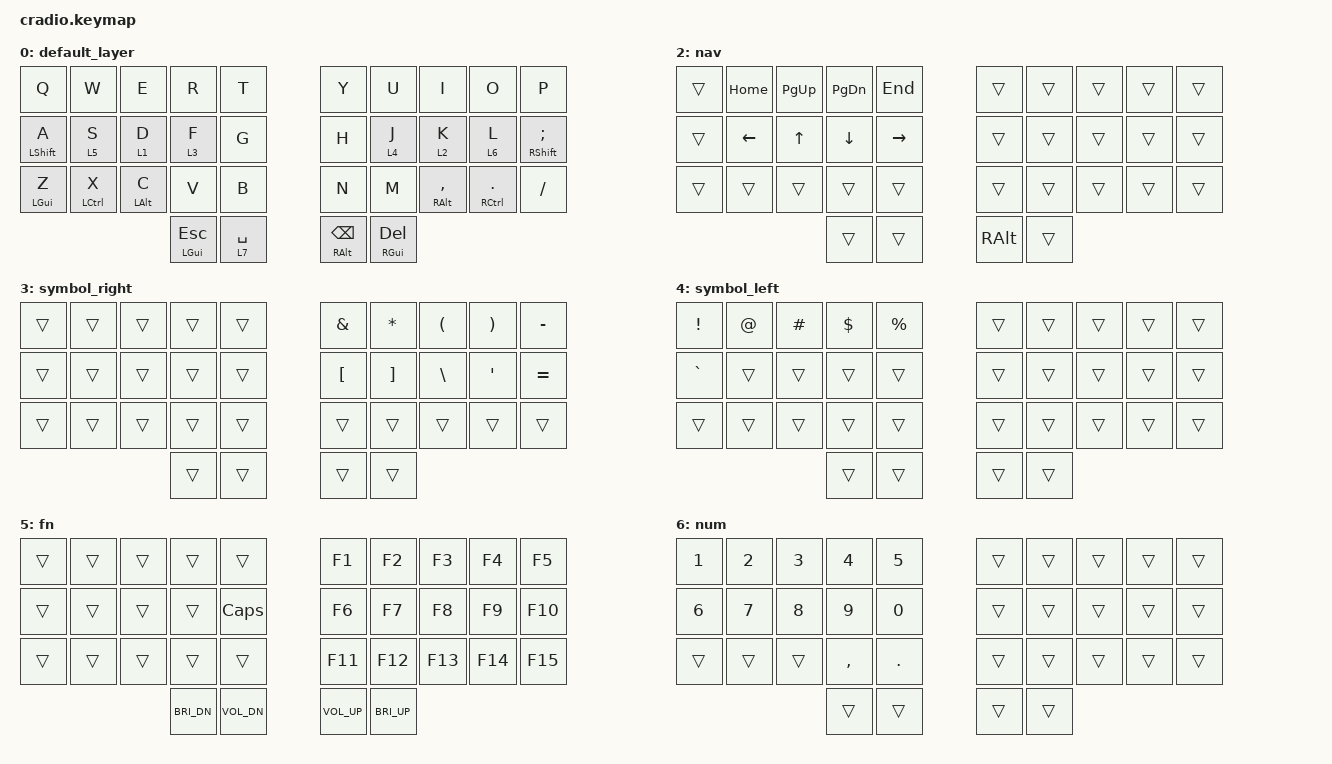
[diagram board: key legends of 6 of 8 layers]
// Copyright (c) 2022 The ZMK Contributors
// SPDX-License-Identifier: MIT

#include <behaviors.dtsi>
#include <dt-bindings/zmk/keys.h>
#include <dt-bindings/zmk/bt.h>
#include <dt-bindings/zmk/mouse.h>
#include <behaviors/mouse_keys.dtsi>


// Home row mods macro
#define HRML(k1,k2,k3,k4) &ht LSHFT k1  &ht LCTRL k2  &ht LALT k3  &ht LGUI k4
#define HRMR(k1,k2,k3,k4) &ht RGUI k1   &ht RALT k2   &ht RCTRL k3 &ht RSHFT k4
#define BTCN(s1,s2,s3,s4,s5) &bt BT_SEL s1 &bt BT_SEL s2 &bt BT_SEL s3 &bt BT_SEL s4 &bt BT_SEL s5
#define BTDN(s1,s2,s3,s4,s5) &bt BT_DISC s1 &bt BT_DISC s2 &bt BT_DISC s3 &bt BT_DISC s4 &bt BT_DISC s5

#define ZMK_MOUSE_DEFAULT_MOVE_VAL 1500  // 600
#define ZMK_MOUSE_DEFAULT_SCRL_VAL 20    // 10

&mmv {
  acceleration-exponent = <1>;      // 1
  time-to-max-speed-ms = <500>;    // 40
  delay-ms = <0>;                   // 0
};

&msc {
  acceleration-exponent = <1>;      // 0
  time-to-max-speed-ms = <500>;      // 500
  delay-ms = <0>;                   // 10
};

#define U_MS_U &mmv MOVE_UP
#define U_MS_D &mmv MOVE_DOWN
#define U_MS_L &mmv MOVE_LEFT
#define U_MS_R &mmv MOVE_RIGHT
#define U_WH_U &msc SCRL_UP
#define U_WH_D &msc SCRL_DOWN
#define U_WH_L &msc SCRL_LEFT
#define U_WH_R &msc SCRL_RIGHT

#define MOUSE() &mkp LCLK &mkp RCLK &mkp MCLK
#define MMV() U_MS_L U_MS_D U_MS_U U_MS_R
#define MSC() U_WH_L U_WH_D U_WH_U U_WH_R


// num, nav, fn, mouse
#define THUMB() &mo 1 &lt 2 SPACE &lt 3 ENTER &lt 4 BSPC

/ {
    behaviors {
        ht: hold_tap {
            label = "hold_tap";
            compatible = "zmk,behavior-hold-tap";
            #binding-cells = <2>;
            flavor = "tap-preferred";
            tapping-term-ms = <200>;
            quick-tap-ms = <150>;
            require-prior-idle-ms = <100>;
            bindings = <&kp>, <&kp>;
        };
    };

    keymap {
        compatible = "zmk,keymap";
        default_layer {
            bindings = <
        //╭──────────┬──────────┬──────────┬──────────┬──────────╮   ╭──────────┬──────────┬──────────┬──────────┬──────────╮
        //│  Q       │  W       │  E       │  R       │  T       │   │  Y       │  U       │  I       │  O       │  P       │
            &kp Q      &kp W      &kp E      &kp R      &kp T          &kp Y      &kp U      &kp I      &kp O      &kp P
        //├──────────┼──────────┼──────────┼──────────┼──────────┤   ├──────────┼──────────┼──────────┼──────────┼──────────┤
        //│  A       │  S       │  D       │  F       │  G       │   │  H       │  J       │  K       │  L       │ ; :      │
           &ht LSHFT A  &lt 5 S   &lt 1 D    &lt 3 F    &kp G          &kp H      &lt 4 J    &lt 2 K    &lt 6 L    &ht RSHFT SEMI
        //├──────────┼──────────┼──────────┼──────────┼──────────┤   ├──────────┼──────────┼──────────┼──────────┼──────────┤
        //│  Z       │  X       │  C       │  V       │  B       │   │  N       │  M       │ , <      │ . >      │ / ?      │
            &ht LGUI Z &ht LCTRL X &ht LALT C &kp V      &kp B         &kp N     &kp M       &ht RALT COMMA  &ht RCTRL DOT &kp FSLH
        //╰──────────┴──────────┴──────────┼──────────┼──────────┤   ├──────────┼──────────┼──────────┴──────────┴──────────╯
                                             &ht LGUI ESC &lt 7 SPACE &ht RALT BSPC &ht RGUI DEL
        //                                 ╰──────────┴──────────╯   ╰──────────┴──────────╯
            >;
        };

        mouse {
            bindings = <
        //╭──────────┬──────────┬──────────┬──────────┬──────────╮   ╭──────────┬──────────┬──────────┬──────────┬──────────╮
        //│          │          │          │          │          │   │          │          │          │          │          │
            &trans     &trans     &trans     &trans     &trans         MSC()                                       &trans
        //├──────────┼──────────┼──────────┼──────────┼──────────┤   ├──────────┼──────────┼──────────┼──────────┼──────────┤
        //│          │          │          │          │          │   │          │          │          │          │          │
            &trans     &trans     &trans     &trans     &trans         MMV()                                       &trans
        //├──────────┼──────────┼──────────┼──────────┼──────────┤   ├──────────┼──────────┼──────────┼──────────┼──────────┤
        //│          │          │          │          │          │   │          │          │          │          │          │
            &trans     &trans     &trans     &trans     &trans         &trans     MOUSE()                          &trans
        //╰──────────┴──────────┴──────────┼──────────┼──────────┤   ├──────────┼──────────┼──────────┴──────────┴──────────╯
                                             &trans     &trans         &trans     &trans
        //                                 ╰──────────┴──────────╯   ╰──────────┴──────────╯
            >;
        };

        nav {
            bindings = <
        //╭──────────┬──────────┬──────────┬──────────┬──────────╮   ╭──────────┬──────────┬──────────┬──────────┬──────────╮
        //│          │          │          │          │          │   │          │          │          │          │          │
            &trans     &kp HOME   &kp PG_UP  &kp PG_DN  &kp END        &trans     &trans     &trans     &trans     &trans
        //├──────────┼──────────┼──────────┼──────────┼──────────┤   ├──────────┼──────────┼──────────┼──────────┼──────────┤
        //│          │          │          │          │          │   │          │          │          │          │          │
            &trans     &kp LEFT   &kp UP     &kp DOWN   &kp RIGHT      &trans     &trans     &trans     &trans     &trans
        //├──────────┼──────────┼──────────┼──────────┼──────────┤   ├──────────┼──────────┼──────────┼──────────┼──────────┤
        //│          │          │          │          │          │   │          │          │          │          │          │
            &trans     &trans     &trans     &trans     &trans         &trans     &trans     &trans     &trans     &trans
        //╰──────────┴──────────┴──────────┼──────────┼──────────┤   ├──────────┼──────────┼──────────┴──────────┴──────────╯
                                             &trans     &trans         &kp RALT   &trans
        //                                 ╰──────────┴──────────╯   ╰──────────┴──────────╯
            >;
        };

        symbol_right {
            bindings = <
        //╭──────────┬──────────┬──────────┬──────────┬──────────╮   ╭──────────┬──────────┬──────────┬──────────┬──────────╮
        //│          │          │          │          │          │   │          │          │          │          │          │
            &trans     &trans     &trans     &trans     &trans         &kp AMPS   &kp ASTRK  &kp LPAR   &kp RPAR   &kp MINUS
        //├──────────┼──────────┼──────────┼──────────┼──────────┤   ├──────────┼──────────┼──────────┼──────────┼──────────┤
        //│          │          │          │          │          │   │          │          │          │          │          │
            &trans     &trans     &trans     &trans     &trans         &kp LBKT   &kp RBKT   &kp BSLH   &kp SQT    &kp EQUAL
        //├──────────┼──────────┼──────────┼──────────┼──────────┤   ├──────────┼──────────┼──────────┼──────────┼──────────┤
        //│          │          │          │          │          │   │          │          │          │          │          │
            &trans     &trans     &trans     &trans     &trans         &trans     &trans     &trans     &trans     &trans
        //╰──────────┴──────────┴──────────┼──────────┼──────────┤   ├──────────┼──────────┼──────────┴──────────┴──────────╯
                                             &trans     &trans         &trans     &trans
        //                                 ╰──────────┴──────────╯   ╰──────────┴──────────╯
            >;
        };

        symbol_left {
            bindings = <
        //╭──────────┬──────────┬──────────┬──────────┬──────────╮   ╭──────────┬──────────┬──────────┬──────────┬──────────╮
        //│          │          │          │          │          │   │          │          │          │          │          │
            &kp EXCL   &kp AT     &kp HASH   &kp DLLR   &kp PRCNT      &trans     &trans     &trans     &trans     &trans
        //├──────────┼──────────┼──────────┼──────────┼──────────┤   ├──────────┼──────────┼──────────┼──────────┼──────────┤
        //│          │          │          │          │          │   │          │          │          │          │          │
            &kp GRAVE  &trans     &trans     &trans     &trans         &trans     &trans     &trans     &trans     &trans
        //├──────────┼──────────┼──────────┼──────────┼──────────┤   ├──────────┼──────────┼──────────┼──────────┼──────────┤
        //│          │          │          │          │          │   │          │          │          │          │          │
            &trans     &trans     &trans     &trans     &trans         &trans     &trans     &trans     &trans     &trans
        //╰──────────┴──────────┴──────────┼──────────┼──────────┤   ├──────────┼──────────┼──────────┴──────────┴──────────╯
                                             &trans     &trans         &trans     &trans
        //                                 ╰──────────┴──────────╯   ╰──────────┴──────────╯
            >;
        };

        fn {
            bindings = <
        //╭──────────┬──────────┬──────────┬──────────┬──────────╮   ╭──────────┬──────────┬──────────┬──────────┬──────────╮
        //│          │          │          │          │          │   │          │          │          │          │          │
            &trans     &trans     &trans     &trans     &trans         &kp F1     &kp F2     &kp F3     &kp F4     &kp F5
        //├──────────┼──────────┼──────────┼──────────┼──────────┤   ├──────────┼──────────┼──────────┼──────────┼──────────┤
        //│          │          │          │          │          │   │          │          │          │          │          │
            &trans     &trans     &trans     &trans     &kp CAPS       &kp F6     &kp F7     &kp F8     &kp F9     &kp F10
        //├──────────┼──────────┼──────────┼──────────┼──────────┤   ├──────────┼──────────┼──────────┼──────────┼──────────┤
        //│          │          │          │          │          │   │          │          │          │          │          │
            &trans     &trans     &trans     &trans     &trans         &kp F11    &kp F12    &kp F13    &kp F14    &kp F15
        //╰──────────┴──────────┴──────────┼──────────┼──────────┤   ├──────────┼──────────┼──────────┴──────────┴──────────╯
                                          &kp C_BRI_DN &kp C_VOL_DN &kp C_VOL_UP &kp C_BRI_UP
        //                                 ╰──────────┴──────────╯   ╰──────────┴──────────╯
            >;
        };

        num {
            bindings = <
        //╭──────────┬──────────┬──────────┬──────────┬──────────╮   ╭──────────┬──────────┬──────────┬──────────┬──────────╮
        //│   1      │  2       │  3       │  4       │ 5        │   │          │          │          │          │          │
            &kp N1     &kp N2     &kp N3     &kp N4     &kp N5         &trans     &trans     &trans     &trans     &trans
        //├──────────┼──────────┼──────────┼──────────┼──────────┤   ├──────────┼──────────┼──────────┼──────────┼──────────┤
        //│  6       │  7       │  8       │  9       │ 0        │   │          │          │          │          │          │
            &kp N6     &kp N7     &kp N8     &kp N9     &kp N0         &trans     &trans     &trans     &trans     &trans
        //├──────────┼──────────┼──────────┼──────────┼──────────┤   ├──────────┼──────────┼──────────┼──────────┼──────────┤
        //│          │          │          │          │          │   │          │          │          │          │          │
            &trans     &trans     &trans     &kp COMMA  &kp DOT        &trans     &trans     &trans     &trans     &trans
        //╰──────────┴──────────┴──────────┼──────────┼──────────┤   ├──────────┼──────────┼──────────┴──────────┴──────────╯
                                             &trans     &trans         &trans     &trans
        //                                 ╰──────────┴──────────╯   ╰──────────┴──────────╯
            >;
        };

        special {
            bindings = <
        //╭──────────┬──────────┬──────────┬──────────┬──────────╮   ╭──────────┬──────────┬──────────┬──────────┬──────────╮
        //│          │          │          │          │          │   │          │          │          │          │          │
           &bt BT_CLR  &trans     &trans     &trans     &trans         &trans     &trans     &trans     &trans     &trans
        //├──────────┼──────────┼──────────┼──────────┼──────────┤   ├──────────┼──────────┼──────────┼──────────┼──────────┤
        //│          │          │          │          │          │   │          │          │          │          │          │
            BTDN(0,       1,         2,         3,         4)          &kp BSPC   &trans     &trans     &trans     &trans 
        //├──────────┼──────────┼──────────┼──────────┼──────────┤   ├──────────┼──────────┼──────────┼──────────┼──────────┤
        //│          │          │          │          │          │   │          │          │          │          │          │
            &trans     &trans     &trans     &trans     &trans         BTCN(0,       1,         2,         3,         4)
        //╰──────────┴──────────┴──────────┼──────────┼──────────┤   ├──────────┼──────────┼──────────┴──────────┴──────────╯
                                             &trans     &trans         &kp TAB    &kp ENTER
        //                                 ╰──────────┴──────────╯   ╰──────────┴──────────╯
            >;
        };
    };
};
